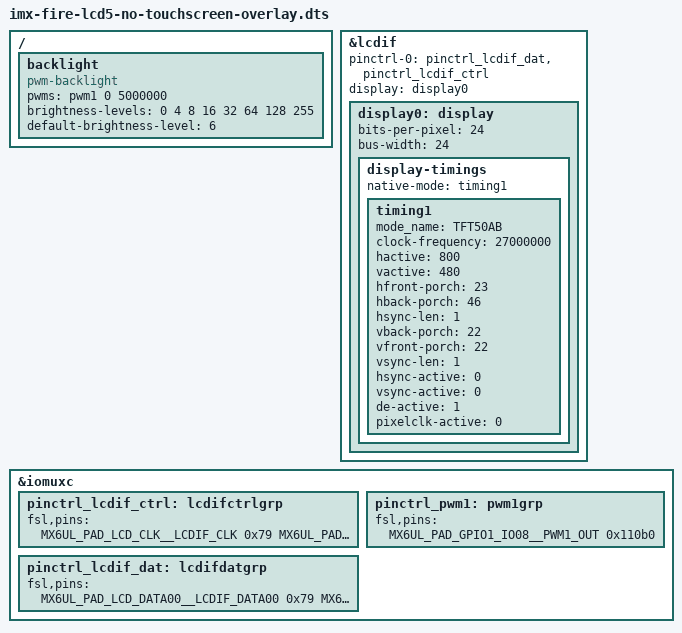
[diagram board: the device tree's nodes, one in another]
/*
 * Copyright (C) 2019 - All Rights Reserved by 
 * filename : imx-fire-mpu6050-overlay.dts
 * brief : Device Tree overlay for ecspi_oled device
 * author : embedfire
 * date : 2019-11-26
 * version : A001
 */



#include "imx6ul-pinfunc.h"
#include "imx6ul-pinfunc.h"
#include "imx6ull-pinfunc-snvs.h"
#include "dt-bindings/gpio/gpio.h"


 /dts-v1/;
 /plugin/;
 / {
     fragment@0 {
         target = <&lcdif>;
         __overlay__ { 
			pinctrl-names = "default";
			pinctrl-0 = <&pinctrl_lcdif_dat &pinctrl_lcdif_ctrl>;
			display = <&display0>;
			status = "okay";
		
			display0: display {
			bits-per-pixel = <24>;
			bus-width = <24>;
				display-timings {
					native-mode = <&timing1>;
					timing1: timing1 {
    			        mode_name = "TFT50AB";
    			        clock-frequency = <27000000>;
    			        hactive = <800>;
    			        vactive = <480>;
    			        hfront-porch = <23>;
    			        hback-porch = <46>;
    			        hsync-len = <1>;
    			        vback-porch = <22>;
    			        vfront-porch = <22>;
    			        vsync-len = <1>;
			
    			        hsync-active = <0>;
    			        vsync-active = <0>;
    			        de-active = <1>;
    			        pixelclk-active = <0>;
					};
				};
			};
         };
     };

     fragment@1 {
         target = <&iomuxc>;
         __overlay__ { 
			pinctrl_lcdif_ctrl: lcdifctrlgrp {
    			fsl,pins = <
    			    MX6UL_PAD_LCD_CLK__LCDIF_CLK	    0x79
    			    MX6UL_PAD_LCD_ENABLE__LCDIF_ENABLE  0x79
    			    MX6UL_PAD_LCD_HSYNC__LCDIF_HSYNC    0x79
    			    MX6UL_PAD_LCD_VSYNC__LCDIF_VSYNC    0x79
    			>;
			};

			pinctrl_lcdif_dat: lcdifdatgrp {
			    fsl,pins = <
			        MX6UL_PAD_LCD_DATA00__LCDIF_DATA00  0x79
			        MX6UL_PAD_LCD_DATA01__LCDIF_DATA01  0x79
			        MX6UL_PAD_LCD_DATA02__LCDIF_DATA02  0x79
			        MX6UL_PAD_LCD_DATA03__LCDIF_DATA03  0x79
			        MX6UL_PAD_LCD_DATA04__LCDIF_DATA04  0x79
			        MX6UL_PAD_LCD_DATA05__LCDIF_DATA05  0x79
			        MX6UL_PAD_LCD_DATA06__LCDIF_DATA06  0x79
			        MX6UL_PAD_LCD_DATA07__LCDIF_DATA07  0x79
			        MX6UL_PAD_LCD_DATA08__LCDIF_DATA08  0x79
			        MX6UL_PAD_LCD_DATA09__LCDIF_DATA09  0x79
			        MX6UL_PAD_LCD_DATA10__LCDIF_DATA10  0x79
			        MX6UL_PAD_LCD_DATA11__LCDIF_DATA11  0x79
			        MX6UL_PAD_LCD_DATA12__LCDIF_DATA12  0x79
			        MX6UL_PAD_LCD_DATA13__LCDIF_DATA13  0x79
			        MX6UL_PAD_LCD_DATA14__LCDIF_DATA14  0x79
			        MX6UL_PAD_LCD_DATA15__LCDIF_DATA15  0x79
			        MX6UL_PAD_LCD_DATA16__LCDIF_DATA16  0x79
			        MX6UL_PAD_LCD_DATA17__LCDIF_DATA17  0x79
			        MX6UL_PAD_LCD_DATA18__LCDIF_DATA18  0x79
			        MX6UL_PAD_LCD_DATA19__LCDIF_DATA19  0x79
			        MX6UL_PAD_LCD_DATA20__LCDIF_DATA20  0x79
			        MX6UL_PAD_LCD_DATA21__LCDIF_DATA21  0x79
			        MX6UL_PAD_LCD_DATA22__LCDIF_DATA22  0x79
			        MX6UL_PAD_LCD_DATA23__LCDIF_DATA23  0x79
			    >;
			};

			pinctrl_pwm1: pwm1grp {
				fsl,pins = <
					MX6UL_PAD_GPIO1_IO08__PWM1_OUT 0x110b0
				>;
			};
         };
     };

     fragment@3 {
         target-path = "/";
         __overlay__ { 
			backlight {
				compatible = "pwm-backlight";   
				pwms = <&pwm1 0 5000000>;
				brightness-levels = <0 4 8 16 32 64 128 255>;
				default-brightness-level = <6>;
				status = "okay";
			};
         };
     };
 };
